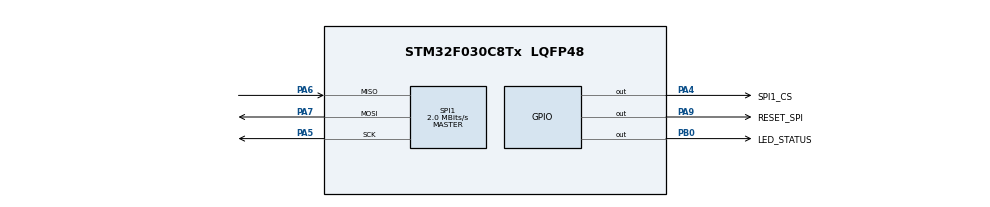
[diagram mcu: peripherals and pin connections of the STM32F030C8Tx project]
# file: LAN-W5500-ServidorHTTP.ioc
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Mcu.Family=STM32F0
RCC.PLLSourceVirtual=RCC_PLLSOURCE_HSE
PA6.Mode=Full_Duplex_Master
PA7.Mode=Full_Duplex_Master
SPI1.VirtualType=VM_MASTER
PA9.GPIO_Label=RESET_SPI
PB0.GPIO_Label=LED_STATUS
ProjectManager.StackSize=0x400
PA13.Signal=SYS_SWDIO
ProjectManager.TargetToolchain=STM32CubeIDE
SPI1.Direction=SPI_DIRECTION_2LINES
PA9.Signal=GPIO_Output
SPI1.CalculateBaudRate=2.0 MBits/s
PF0-OSC_IN.Mode=HSE-External-Oscillator
PA5.Signal=SPI1_SCK
board=custom
PA4.GPIO_Speed=GPIO_SPEED_FREQ_MEDIUM
SPI1.Mode=SPI_MODE_MASTER
PA14.Mode=Serial_Wire
SPI1.DataSize=SPI_DATASIZE_8BIT
PA13.Mode=Serial_Wire
Mcu.Name=STM32F030C8Tx
PA4.Signal=GPIO_Output
Mcu.Package=LQFP48
PA6.Signal=SPI1_MISO
PA14.Signal=SYS_SWCLK
ProjectManager.HeapSize=0x200
PA9.GPIO_Speed=GPIO_SPEED_FREQ_MEDIUM
PF0-OSC_IN.Signal=RCC_OSC_IN
PF1-OSC_OUT.Mode=HSE-External-Oscillator
SPI1.BaudRatePrescaler=SPI_BAUDRATEPRESCALER_4
PB0.Signal=GPIO_Output
PA4.GPIO_Label=SPI1_CS
PF1-OSC_OUT.Signal=RCC_OSC_OUT
PA5.Mode=Full_Duplex_Master
PA7.Signal=SPI1_MOSI

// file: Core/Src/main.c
/* USER CODE BEGIN Header */
/**
  ******************************************************************************
  * @file           : main.c
  * @brief          : Main program body
  ******************************************************************************
  * @attention
  *
  * <h2><center>&copy; Copyright (c) 2021 STMicroelectronics.
  * All rights reserved.</center></h2>
  *
  * This software component is licensed by ST under BSD 3-Clause license,
  * the "License"; You may not use this file except in compliance with the
  * License. You may obtain a copy of the License at:
  *                        opensource.org/licenses/BSD-3-Clause
  *
  ******************************************************************************
  */
/* USER CODE END Header */

#include "main.h"

/* USER CODE BEGIN Includes */

#include <stdio.h>
#include "net.h"

/* USER CODE END Includes */

SPI_HandleTypeDef hspi1;

void SystemClock_Config(void);
static void MX_GPIO_Init(void);
static void MX_SPI1_Init(void);
/* USER CODE BEGIN PFP */

extern void initialise_monitor_handles(void);

/* USER CODE END PFP */

int main(void)
{
  /* USER CODE BEGIN 1 */

	initialise_monitor_handles();

  /* USER CODE END 1 */

  /* MCU Configuration--------------------------------------------------------*/

  /* Reset of all peripherals, Initializes the Flash interface and the Systick. */
  HAL_Init();

  /* Configure the system clock */
  SystemClock_Config();

  /* Initialize all configured peripherals */
  MX_GPIO_Init();
  MX_SPI1_Init();
  /* USER CODE BEGIN 2 */

  net_ini();

  /* USER CODE END 2 */

  /* Infinite loop */
  while (1)
  {

    /* USER CODE BEGIN 3 */
	  net_poll();

	  HAL_GPIO_TogglePin(LED_STATUS_GPIO_Port, LED_STATUS_Pin);
	  printf("Blink Led\n");
	  HAL_Delay(1000);
  }
  /* USER CODE END 3 */
}

void SystemClock_Config(void)
{
  RCC_OscInitTypeDef RCC_OscInitStruct = {0};
  RCC_ClkInitTypeDef RCC_ClkInitStruct = {0};

  /** Initializes the CPU, AHB and APB busses clocks
  */
  RCC_OscInitStruct.OscillatorType = RCC_OSCILLATORTYPE_HSI;
  RCC_OscInitStruct.HSIState = RCC_HSI_ON;
  RCC_OscInitStruct.HSICalibrationValue = RCC_HSICALIBRATION_DEFAULT;
  RCC_OscInitStruct.PLL.PLLState = RCC_PLL_NONE;
  if (HAL_RCC_OscConfig(&RCC_OscInitStruct) != HAL_OK)
  {
    Error_Handler();
  }
  /** Initializes the CPU, AHB and APB busses clocks
  */
  RCC_ClkInitStruct.ClockType = RCC_CLOCKTYPE_HCLK|RCC_CLOCKTYPE_SYSCLK
                              |RCC_CLOCKTYPE_PCLK1;
  RCC_ClkInitStruct.SYSCLKSource = RCC_SYSCLKSOURCE_HSI;
  RCC_ClkInitStruct.AHBCLKDivider = RCC_SYSCLK_DIV1;
  RCC_ClkInitStruct.APB1CLKDivider = RCC_HCLK_DIV1;

  if (HAL_RCC_ClockConfig(&RCC_ClkInitStruct, FLASH_LATENCY_0) != HAL_OK)
  {
    Error_Handler();
  }
}

static void MX_SPI1_Init(void)
{

  /* SPI1 parameter configuration*/
  hspi1.Instance = SPI1;
  hspi1.Init.Mode = SPI_MODE_MASTER;
  hspi1.Init.Direction = SPI_DIRECTION_2LINES;
  hspi1.Init.DataSize = SPI_DATASIZE_8BIT;
  hspi1.Init.CLKPolarity = SPI_POLARITY_LOW;
  hspi1.Init.CLKPhase = SPI_PHASE_1EDGE;
  hspi1.Init.NSS = SPI_NSS_SOFT;
  hspi1.Init.BaudRatePrescaler = SPI_BAUDRATEPRESCALER_4;
  hspi1.Init.FirstBit = SPI_FIRSTBIT_MSB;
  hspi1.Init.TIMode = SPI_TIMODE_DISABLE;
  hspi1.Init.CRCCalculation = SPI_CRCCALCULATION_DISABLE;
  hspi1.Init.CRCPolynomial = 7;
  hspi1.Init.CRCLength = SPI_CRC_LENGTH_DATASIZE;
  hspi1.Init.NSSPMode = SPI_NSS_PULSE_ENABLE;
  if (HAL_SPI_Init(&hspi1) != HAL_OK)
  {
    Error_Handler();
  }

}

static void MX_GPIO_Init(void)
{
  GPIO_InitTypeDef GPIO_InitStruct = {0};

  /* GPIO Ports Clock Enable */
  __HAL_RCC_GPIOF_CLK_ENABLE();
  __HAL_RCC_GPIOA_CLK_ENABLE();
  __HAL_RCC_GPIOB_CLK_ENABLE();

  /*Configure GPIO pin Output Level */
  HAL_GPIO_WritePin(GPIOA, SPI1_CS_Pin|RESET_SPI_Pin, GPIO_PIN_RESET);

  /*Configure GPIO pin Output Level */
  HAL_GPIO_WritePin(LED_STATUS_GPIO_Port, LED_STATUS_Pin, GPIO_PIN_RESET);

  /*Configure GPIO pins : SPI1_CS_Pin RESET_SPI_Pin */
  GPIO_InitStruct.Pin = SPI1_CS_Pin|RESET_SPI_Pin;
  GPIO_InitStruct.Mode = GPIO_MODE_OUTPUT_PP;
  GPIO_InitStruct.Pull = GPIO_NOPULL;
  GPIO_InitStruct.Speed = GPIO_SPEED_FREQ_MEDIUM;
  HAL_GPIO_Init(GPIOA, &GPIO_InitStruct);

  /*Configure GPIO pin : LED_STATUS_Pin */
  GPIO_InitStruct.Pin = LED_STATUS_Pin;
  GPIO_InitStruct.Mode = GPIO_MODE_OUTPUT_PP;
  GPIO_InitStruct.Pull = GPIO_NOPULL;
  GPIO_InitStruct.Speed = GPIO_SPEED_FREQ_LOW;
  HAL_GPIO_Init(LED_STATUS_GPIO_Port, &GPIO_InitStruct);

}

void Error_Handler(void)
{
}

/************************ (C) COPYRIGHT STMicroelectronics *****END OF FILE****/
